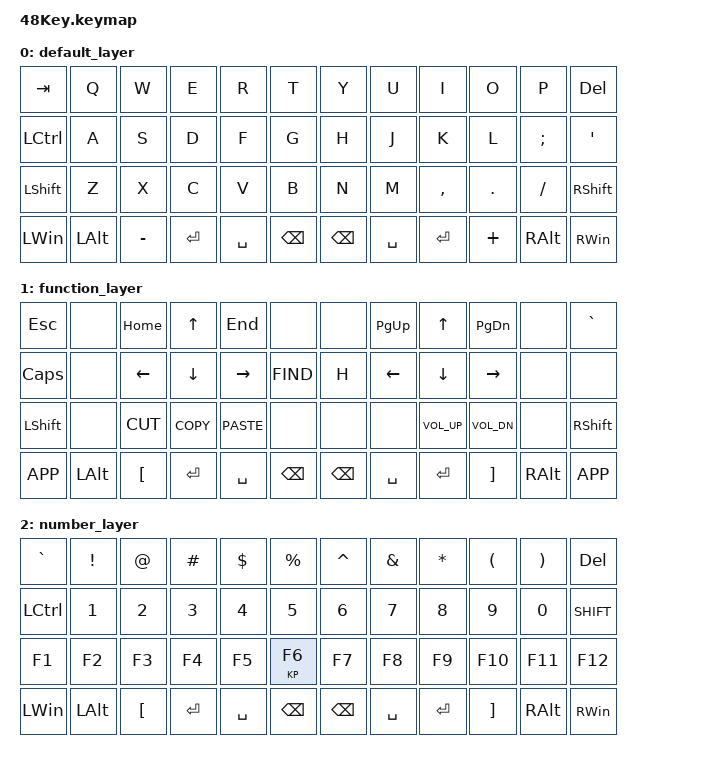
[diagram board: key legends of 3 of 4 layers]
/*
 * Copyright (c) 2022 The ZMK Contributors
 *
 * SPDX-License-Identifier: MIT
 */

#include <behaviors.dtsi>
#include <dt-bindings/zmk/keys.h>
#include <dt-bindings/zmk/bt.h>

#define DEFAULT 0
#define function 1
#define number 2
#define settings 3

/ {
    keymap {
        compatible = "zmk,keymap";

        default_layer {
//--------------------------------------------------------------------------------------------------------
// |  TAB  |  Q  |  W  | E |  R  |   T   |                       |   Y   |  U  | I |  O  |  P  |  DEL  |
// |  CTL  |  A  |  S  | D |  F  |   G   |                       |   H   |  J  | K |  L  |  ;  |   '   |
// | SHIFT |  Z  |  X  | C |  V  |   B   |                       |   N   |  M  | , |  .  |  /  | SHIFT |
//         | WIN | ALT | - | ENT | SPACE | BKSP |         | BKSP | SPACE | ENT | = | ALT | WIN |
            bindings = <
                &kp TAB      &kp Q      &kp W      &kp E      &kp R      &kp T      &kp Y      &kp  U      &kp I      &kp O      &kp P      &kp DEL
                &kp LCTRL      &kp A      &kp S      &kp D      &kp F      &kp G      &kp H      &kp  J      &kp K      &kp L      &kp SEMI      &kp SQT
                &kp LSHIFT      &kp Z      &kp X      &kp C      &kp V      &kp B      &kp N      &kp  M      &kp COMMA      &kp DOT      &kp FSLH      &kp RSHIFT
                &kp LWIN      &kp LALT      &kp MINUS      &kp ENTER      &kp SPACE      &kp BSPC      &kp BSPC      &kp  SPACE      &kp ENTER      &kp PLUS      &kp RALT      &kp RWIN
            >;
         };
        function_layer {
//--------------------------------------------------------------------------------------------------------------------------
// |  ESC  |     | HOME | UP |  END  |       |                           |       | PG_UP |   UP   | PG_DN  |     |   `   |
// |  CAP  |     | LEFT | DN | RIGHT | FIND  |                           |       |  LEFT |  DOWN  | RIGHT  |     |       |
// | SHIFT |     |  CUT | CP |  PST  |       |                           |       |       | Vol_UP | VOL_DN |     | SHIFT |
//         | APP | ALT  | [  |  ENT  | SPACE | BKSP |             | BKSP | SPACE |  ENT  |    ]   |   ALT  | APP |
            bindings = <
                &kp ESC      &none      &kp HOME      &kp UP      &kp END      &none      &none      &kp  PG_UP      &kp UP      &kp PG_DN      &none      &kp GRAVE
                &kp CAPS      &none      &kp LEFT      &kp DOWN      &kp RIGHT      &kp K_FIND      &kp H      &kp  LEFT      &kp DOWN      &kp RIGHT      &none      &none
                &kp LSHIFT      &none      &kp K_CUT      &kp K_COPY      &kp K_PASTE      &none      &none      &none      &kp C_VOL_UP      &kp C_VOL_DN      &none      &kp RSHIFT
                &kp K_APP      &kp LALT      &kp LBKT      &kp ENTER      &kp SPACE      &kp BSPC      &kp BSPC      &kp  SPACE      &kp ENTER      &kp RBKT      &kp RALT      &kp K_APP
            >;
        };
        number_layer {
//---------------------------------------------------------------------------------------------------------
// |  `  |  !  |  @  | #  | $   |    %  |                        |   ^   | &   | *  |  (  |  )  |  DEL  |
// | CTL |  1  |  2  | 3  | 4   |    5  |                        |   6   | 7   | 8  |  9  |  0  | SHIFT |
// | F1  |  F2 |  F3 | F4 | F5  |   F6  |                        |   F7  | F8  | F9 | F10 | F11 |  F12  |
//       | WIN | ALT | [  | ENT | SPACE | BKSP |          | BKSP | SPACE | ENT | ]  | ALT | APP |
            bindings = <
                &kp GRAVE      &kp EXCL      &kp AT      &kp HASH      &kp DOLLAR      &kp PERCENT      &kp CARET      &kp  AMPS      &kp ASTERISK      &kp LPAR      &kp RPAR      &kp DEL
                &kp LCTRL      &kp 1      &kp 2      &kp 3      &kp 4      &kp 5      &kp 6      &kp 7      &kp 8      &kp 9      &kp 0      &kp SHIFT
                &kp F1      &kp F2      &kp F3      &kp F4      &kp F5      &KP F6      &kp F7      &kp F8      &kp F9      &kp F10      &kp F11     &kp F12
                &kp LWIN      &kp LALT      &kp LBKT      &kp ENTER      &kp SPACE      &kp BSPC      &kp BSPC      &kp  SPACE      &kp ENTER      &kp RBKT      &kp RALT      &kp RWIN
            >;
         };
        settings_layer {
//---------------------------------------------------------------------------------------------------------------------
// | BT SL 0 | BT SL 1  |  BT SL 2  | BT SL 3 | BT SL 4  |  |                     |  |  |  |  |            | BT_CLR |
// | BT DC 0 | BT DC 1  |  BT DC 2  | BT DC 3 | BT DC 4  |  |                     |  |  |  |  |            |        |
// |         |          |           |         |          |  |                     |  |  |  |  |            |        |
//           |          |           |         |          |  | BT PRV |   | BT NXT |  |  |  |  | BT_CLR_ALL |
            bindings = <
                &bt BT_SEL 0      &bt BT_SEL 1      &bt BT_SEL 2      &bt BT_SEL 3      &bt BT_SEL 4     &none      &none      &none     &none      &none      &bt BT_CLR
                &bt BT_DISC 0      &bt BT_DISC 1      &bt BT_DISC 2      &bt BT_DISC 3      &bt BT_DISC 4      &none      &none      &none      &none      &none      &none      &none
                &none      &none      &none      &none      &none      &none      &none      &none      &none      &none      &none      &none
                &none      &none      &none      &none      &none      &bt BT_PRV      &bt BT_NXT      &none      &none      &none      &none      &bt BT_CLR_ALL
            >;
         };
    };
};
